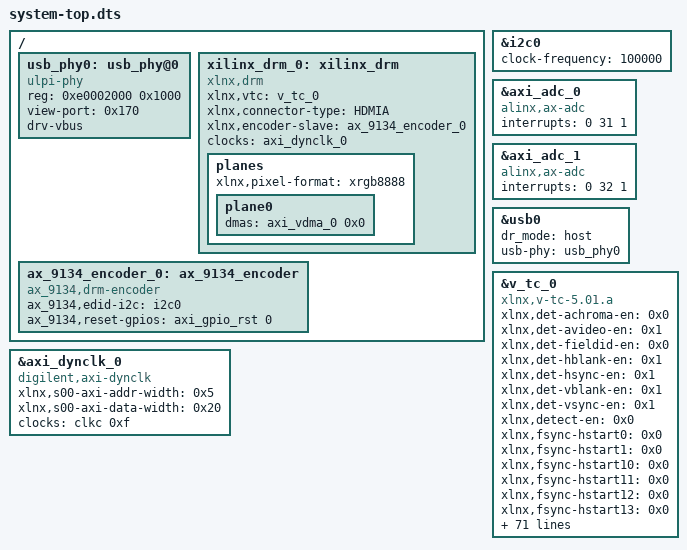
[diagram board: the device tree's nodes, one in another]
/dts-v1/;
/include/ "system-conf.dtsi"
/ {
	usb_phy0:usb_phy@0 {
		compatible = "ulpi-phy";
		#phy-cells = <0x0>;
		reg = <0xe0002000 0x1000>;
		view-port=<0x170>;
		drv-vbus;
	};
	xilinx_drm_0: xilinx_drm {
		compatible = "xlnx,drm";
		xlnx,vtc = <&v_tc_0>;
		xlnx,connector-type = "HDMIA";
		xlnx,encoder-slave = <&ax_9134_encoder_0>;
		clocks = <&axi_dynclk_0>;
		planes {
			xlnx,pixel-format = "xrgb8888";
			plane0 {
				dmas = <&axi_vdma_0 0x0>;
				dma-names = "dma";
			};
		};
	};
	ax_9134_encoder_0: ax_9134_encoder {
		compatible = "ax_9134,drm-encoder";
		ax_9134,edid-i2c = <&i2c0>;
		ax_9134,reset-gpios = <&axi_gpio_rst 0 0>;
	};

};

&i2c0 {
	clock-frequency = <100000>;
	status = "okay";
};


&axi_adc_0{
	compatible = "alinx,ax-adc";
	interrupts = <0 31 1>;
};
&axi_adc_1{
	compatible = "alinx,ax-adc";
	interrupts = <0 32 1>;
};


&usb0 {
    status = "okay";
    dr_mode = "host";
    usb-phy = <&usb_phy0>;
};



&axi_dynclk_0 {
	compatible = "digilent,axi-dynclk";
	#clock-cells = <0x0>;
	xlnx,s00-axi-addr-width = <0x5>;
	xlnx,s00-axi-data-width = <0x20>;
	clocks = <&clkc 0xf>;
};

&v_tc_0 {
	compatible = "xlnx,v-tc-5.01.a";
	xlnx,det-achroma-en = <0x0>;
	xlnx,det-avideo-en = <0x1>;
	xlnx,det-fieldid-en = <0x0>;
	xlnx,det-hblank-en = <0x1>;
	xlnx,det-hsync-en = <0x1>;
	xlnx,det-vblank-en = <0x1>;
	xlnx,det-vsync-en = <0x1>;
	xlnx,detect-en = <0x0>;
	xlnx,fsync-hstart0 = <0x0>;
	xlnx,fsync-hstart1 = <0x0>;
	xlnx,fsync-hstart10 = <0x0>;
	xlnx,fsync-hstart11 = <0x0>;
	xlnx,fsync-hstart12 = <0x0>;
	xlnx,fsync-hstart13 = <0x0>;
	xlnx,fsync-hstart14 = <0x0>;
	xlnx,fsync-hstart15 = <0x0>;
	xlnx,fsync-hstart2 = <0x0>;
	xlnx,fsync-hstart3 = <0x0>;
	xlnx,fsync-hstart4 = <0x0>;
	xlnx,fsync-hstart5 = <0x0>;
	xlnx,fsync-hstart6 = <0x0>;
	xlnx,fsync-hstart7 = <0x0>;
	xlnx,fsync-hstart8 = <0x0>;
	xlnx,fsync-hstart9 = <0x0>;
	xlnx,fsync-vstart0 = <0x0>;
	xlnx,fsync-vstart1 = <0x0>;
	xlnx,fsync-vstart10 = <0x0>;
	xlnx,fsync-vstart11 = <0x0>;
	xlnx,fsync-vstart12 = <0x0>;
	xlnx,fsync-vstart13 = <0x0>;
	xlnx,fsync-vstart14 = <0x0>;
	xlnx,fsync-vstart15 = <0x0>;
	xlnx,fsync-vstart2 = <0x0>;
	xlnx,fsync-vstart3 = <0x0>;
	xlnx,fsync-vstart4 = <0x0>;
	xlnx,fsync-vstart5 = <0x0>;
	xlnx,fsync-vstart6 = <0x0>;
	xlnx,fsync-vstart7 = <0x0>;
	xlnx,fsync-vstart8 = <0x0>;
	xlnx,fsync-vstart9 = <0x0>;
	xlnx,gen-achroma-en = <0x0>;
	xlnx,gen-achroma-polarity = <0x1>;
	xlnx,gen-auto-switch = <0x0>;
	xlnx,gen-avideo-en = <0x1>;
	xlnx,gen-avideo-polarity = <0x1>;
	xlnx,gen-cparity = <0x0>;
	xlnx,gen-f0-vblank-hend = <0x500>;
	xlnx,gen-f0-vblank-hstart = <0x500>;
	xlnx,gen-f0-vframe-size = <0x2ee>;
	xlnx,gen-f0-vsync-hend = <0x500>;
	xlnx,gen-f0-vsync-hstart = <0x500>;
	xlnx,gen-f0-vsync-vend = <0x2d9>;
	xlnx,gen-f0-vsync-vstart = <0x2d4>;
	xlnx,gen-f1-vblank-hend = <0x500>;
	xlnx,gen-f1-vblank-hstart = <0x500>;
	xlnx,gen-f1-vframe-size = <0x2ee>;
	xlnx,gen-f1-vsync-hend = <0x500>;
	xlnx,gen-f1-vsync-hstart = <0x500>;
	xlnx,gen-f1-vsync-vend = <0x2d9>;
	xlnx,gen-f1-vsync-vstart = <0x2d4>;
	xlnx,gen-fieldid-en = <0x0>;
	xlnx,gen-fieldid-polarity = <0x1>;
	xlnx,gen-hactive-size = <0x500>;
	xlnx,gen-hblank-en = <0x1>;
	xlnx,gen-hblank-polarity = <0x1>;
	xlnx,gen-hframe-size = <0x672>;
	xlnx,gen-hsync-en = <0x1>;
	xlnx,gen-hsync-end = <0x596>;
	xlnx,gen-hsync-polarity = <0x1>;
	xlnx,gen-hsync-start = <0x56e>;
	xlnx,gen-interlaced = <0x0>;
	xlnx,gen-vactive-size = <0x2d0>;
	xlnx,gen-vblank-en = <0x1>;
	xlnx,gen-vblank-polarity = <0x1>;
	xlnx,gen-video-format = <0x2>;
	xlnx,gen-vsync-en = <0x1>;
	xlnx,gen-vsync-polarity = <0x1>;
	xlnx,generate-en = <0x1>;
	xlnx,has-axi4-lite = <0x1>;
	xlnx,has-intc-if = <0x0>;
	xlnx,interlace-en = <0x0>;
	xlnx,max-lines = <0x1000>;
	xlnx,max-pixels = <0x1000>;
	xlnx,num-fsyncs = <0x1>;
	xlnx,sync-en = <0x0>;
};

